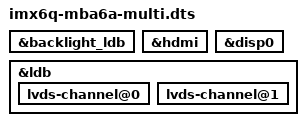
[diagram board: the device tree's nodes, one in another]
/*
 * Copyright 2014 Markus Niebel, TQ Systems GmbH
 *
 * The code contained herein is licensed under the GNU General Public
 * License. You may obtain a copy of the GNU General Public License
 * Version 2 or later at the following locations:
 *
 * http://www.opensource.org/licenses/gpl-license.html
 * http://www.gnu.org/copyleft/gpl.html
 */

#include "imx6q-mba6a.dts"

&backlight_ldb {
	status = "okay";
};

&hdmi {
	status = "okay";
};

&disp0 {
	status = "okay";
};

&ldb {
	status = "okay";

	lvds-channel@0 {
		status = "okay";
	};
	lvds-channel@1 {
		status = "okay";
	};
};
